# ATSAMC20N17A register map
Vendor: Microchip Technology; Series: SAMC20; File version: 0
CPU: CM0+ r0p0, selectable endian, MPU, no FPU, VTOR, 2 interrupt priority bits
Registers are 32-bit, read-write, reset 0x0 unless marked. A register's access mark holds for its fields unless they carry their own. Offsets are from the block's base; [hi:lo] are bit positions; lines under a group give offsets from that group; {n}, {i} and the like mark numbered series; 'fields as' and 'values as' point back to an identical list.

## PAC — Peripheral Access Controller
Base 0x40000000; register names take the prefix PAC_
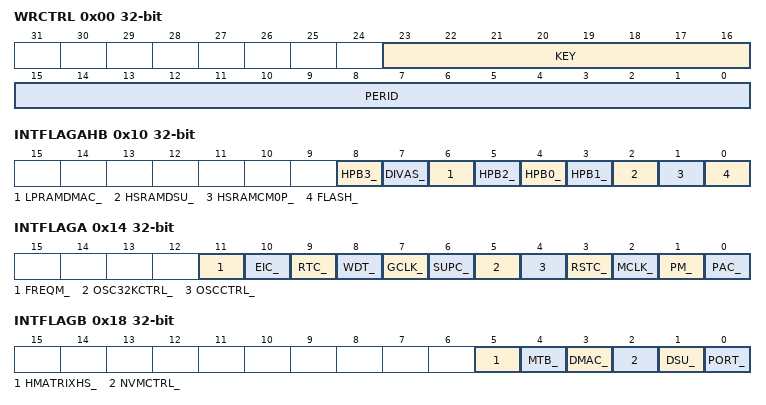
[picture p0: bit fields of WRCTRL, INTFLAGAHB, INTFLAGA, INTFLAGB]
0x00 WRCTRL — Write control
  [23:16] KEY — Peripheral access control key
    0=OFF (No action); 1=CLR (Clear protection); 2=SET (Set protection); 3=SETLCK (Set and lock protection)
  [15:0] PERID — Peripheral identifier
0x04 EVCTRL 8-bit — Event control
  [0] ERREO — Peripheral acess error event output
0x08 INTENCLR 8-bit — Interrupt enable clear
  [0] ERR — Peripheral access error interrupt disable
0x09 INTENSET 8-bit — Interrupt enable set
  [0] ERR — Peripheral access error interrupt enable
0x10 INTFLAGAHB — Bridge interrupt flag status
  [8] HPB3_, [7] DIVAS_, [6] LPRAMDMAC_, [5] HPB2_, [4] HPB0_, [3] HPB1_, [2] HSRAMDSU_, [1] HSRAMCM0P_, [0] FLASH_
0x14 INTFLAGA — Peripheral interrupt flag status - Bridge A
  [11] FREQM_, [10] EIC_, [9] RTC_, [8] WDT_, [7] GCLK_, [6] SUPC_, [5] OSC32KCTRL_, [4] OSCCTRL_, [3] RSTC_, [2] MCLK_, [1] PM_, [0] PAC_
0x18 INTFLAGB — Peripheral interrupt flag status - Bridge B
  [5] HMATRIXHS_, [4] MTB_, [3] DMAC_, [2] NVMCTRL_, [1] DSU_, [0] PORT_
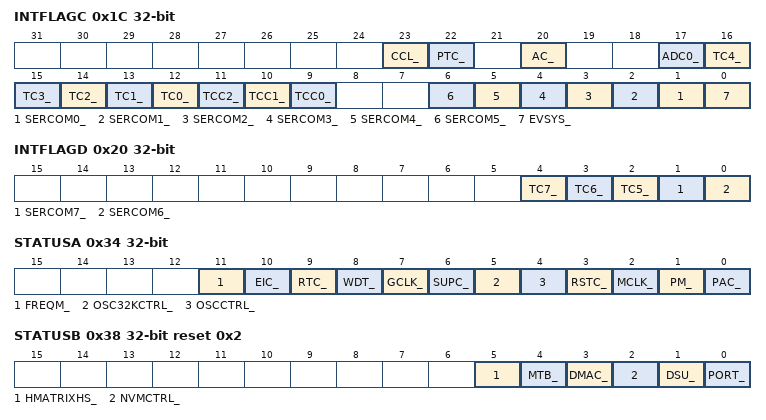
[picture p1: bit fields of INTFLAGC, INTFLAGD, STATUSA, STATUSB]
0x1C INTFLAGC — Peripheral interrupt flag status - Bridge C
  [23] CCL_, [22] PTC_, [20] AC_, [17] ADC0_, [n+12] TC{n}_ (n=0..4), [11] TCC2_, [10] TCC1_, [9] TCC0_, [n+1] SERCOM{n}_ (n=0..5), [0] EVSYS_
0x20 INTFLAGD — Peripheral interrupt flag status - Bridge D
  [4] TC7_, [3] TC6_, [2] TC5_, [1] SERCOM7_, [0] SERCOM6_
0x34 STATUSA ro — Peripheral write protection status - Bridge A
  [11] FREQM_ — FREQM APB Protect Enable
  [10] EIC_ — EIC APB Protect Enable
  [9] RTC_ — RTC APB Protect Enable
  [8] WDT_ — WDT APB Protect Enable
  [7] GCLK_ — GCLK APB Protect Enable
  [6] SUPC_ — SUPC APB Protect Enable
  [5] OSC32KCTRL_ — OSC32KCTRL APB Protect Enable
  [4] OSCCTRL_ — OSCCTRL APB Protect Enable
  [3] RSTC_ — RSTC APB Protect Enable
  [2] MCLK_ — MCLK APB Protect Enable
  [1] PM_ — PM APB Protect Enable
  [0] PAC_ — PAC APB Protect Enable
0x38 STATUSB ro reset 0x2 — Peripheral write protection status - Bridge B
  [5] HMATRIXHS_ — HMATRIXHS APB Protect Enable
  [4] MTB_ — MTB APB Protect Enable
  [3] DMAC_ — DMAC APB Protect Enable
  [2] NVMCTRL_ — NVMCTRL APB Protect Enable
  [1] DSU_ — DSU APB Protect Enable
  [0] PORT_ — PORT APB Protect Enable
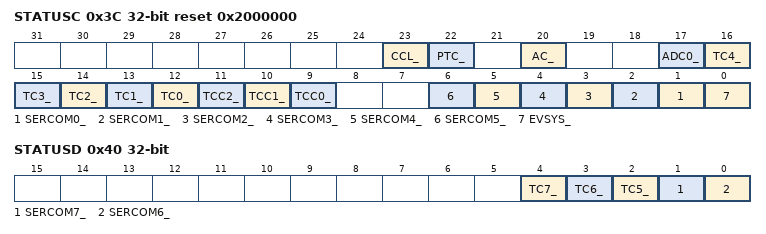
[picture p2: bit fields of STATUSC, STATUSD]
0x3C STATUSC ro reset 0x2000000 — Peripheral write protection status - Bridge C
  [23] CCL_ — CCL APB Protect Enable
  [22] PTC_ — PTC APB Protect Enable
  [20] AC_ — AC APB Protect Enable
  [17] ADC0_ — ADC0 APB Protect Enable
  [n+12] TC{n}_ (n=0..4) — TC{n} APB Protect Enable
  [11] TCC2_ — TCC2 APB Protect Enable
  [10] TCC1_ — TCC1 APB Protect Enable
  [9] TCC0_ — TCC0 APB Protect Enable
  [n+1] SERCOM{n}_ (n=0..5) — SERCOM{n} APB Protect Enable
  [0] EVSYS_ — EVSYS APB Protect Enable
0x40 STATUSD ro — Peripheral write protection status - Bridge D
  [4] TC7_ — TC7 APB Protect Enable
  [3] TC6_ — TC6 APB Protect Enable
  [2] TC5_ — TC5 APB Protect Enable
  [1] SERCOM7_ — SERCOM7 APB Protect Enable
  [0] SERCOM6_ — SERCOM6 APB Protect Enable

## PM — Power Manager
Base 0x40000400; register names take the prefix PM_
0x01 SLEEPCFG 8-bit — Sleep Configuration
  [2:0] SLEEPMODE
    2=IDLE (CPU, AHBx, and APBx clocks are OFF); 4=STANDBY (All Clocks are OFF)
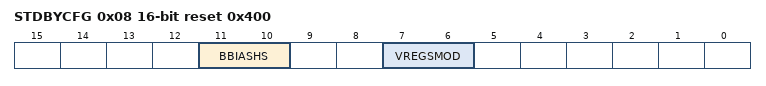
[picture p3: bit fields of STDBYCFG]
0x08 STDBYCFG 16-bit reset 0x400 — Standby Configuration
  [11:10] BBIASHS — Back Bias for HMCRAMCHS
  [7:6] VREGSMOD — Voltage Regulator Standby mode
    0=AUTO (Automatic mode); 1=PERFORMANCE (Performance oriented); 2=LP (Low Power oriented)

## PORT — Port Module
Base 0x41000000; register names take the prefix PORT_
Same registers: PORT_IOBUS 0x60000000 (register names take the prefix PORT_IOBUS_)
{0x0+0x80*i} GROUP[{i}] (i=0..2) group
  0x00 DIR — Data Direction
  0x04 DIRCLR — Data Direction Clear
  0x08 DIRSET — Data Direction Set
  0x0C DIRTGL — Data Direction Toggle
  0x10 OUT — Data Output Value
  0x14 OUTCLR — Data Output Value Clear
  0x18 OUTSET — Data Output Value Set
  0x1C OUTTGL — Data Output Value Toggle
  0x20 IN ro — Data Input Value
  0x24 CTRL — Control
    [31:0] SAMPLING — Input Sampling Mode
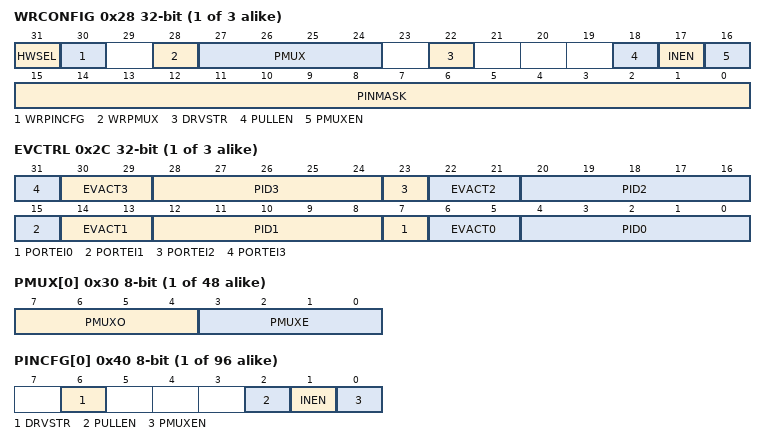
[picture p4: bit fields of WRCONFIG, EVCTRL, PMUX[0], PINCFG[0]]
  0x28 WRCONFIG wo — Write Configuration
    [31] HWSEL — Half-Word Select
    [30] WRPINCFG — Write PINCFG Registers
    [28] WRPMUX — Write PMUX Registers
    [27:24] PMUX — Peripheral Multiplexing Template
    [22] DRVSTR — Output Driver Strength Selection
    [18] PULLEN — Pull Enable
    [17] INEN — Input Enable
    [16] PMUXEN — Select Peripheral Multiplexer
    [15:0] PINMASK — Pin Mask for Multiple Pin Configuration
  0x2C EVCTRL — Event Input Control
    [8n+7] PORTEI{n} (n=0..3) — Port Event Enable Input {n}
    [30:29] EVACT3 — Port Event Action 3
    [8n+4:8n] PID{n} (n=0..3) — Port Event Pin Identifier {n}
    [22:21] EVACT2 — Port Event Action 2
    [14:13] EVACT1 — Port Event Action 1
    [6:5] EVACT0 — Port Event Action 0
      0=OUT (Event output to pin); 1=SET (Set output register of pin on event); 2=CLR (Clear output register of pin on event); 3=TGL (Toggle output register of pin on event)
  {0x30+j} PMUX[{j}] (j=0..15) 8-bit — Peripheral Multiplexing n
    [7:4] PMUXO — Peripheral Multiplexing for Odd-Numbered Pin
      0=A (Peripheral function A selected); 1=B (Peripheral function B selected); 2=C (Peripheral function C selected); 3=D (Peripheral function D selected); 4=E (Peripheral function E selected); 5=F (Peripheral function F selected); 6=G (Peripheral function G selected); 7=H (Peripheral function H selected); 8=I (Peripheral function I selected)
    [3:0] PMUXE — Peripheral Multiplexing for Even-Numbered Pin
      values as PMUXO
  {0x40+j} PINCFG[{j}] (j=0..31) 8-bit — Pin Configuration n
    [6] DRVSTR — Output Driver Strength Selection
    [2] PULLEN — Pull Enable
    [1] INEN — Input Enable
    [0] PMUXEN — Select Peripheral Multiplexer
